# STM32F40x register map
File version: 1.5
Registers are 32-bit, read-write, reset 0x0 unless marked. A register's access mark holds for its fields unless they carry their own. Offsets are from the block's base; [hi:lo] are bit positions; {n}, {i} and the like mark numbered series; 'fields as' and 'values as' point back to an identical list.

## RTC（实时时钟） — 实时时钟：日历/闹钟/唤醒 | Real-time clock
Base 0x40002800
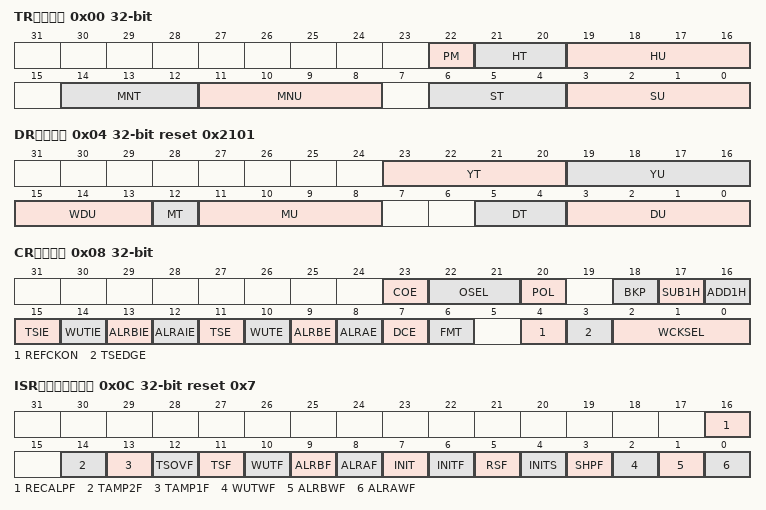
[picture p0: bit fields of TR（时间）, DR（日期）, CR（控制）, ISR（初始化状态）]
0x00 TR（时间） — BCD 时间（时/分/秒） | time register
  [22] PM — AM/PM notation
  [21:20] HT — Hour tens in BCD format
  [19:16] HU — Hour units in BCD format
  [14:12] MNT — Minute tens in BCD format
  [11:8] MNU — Minute units in BCD format
  [6:4] ST — Second tens in BCD format
  [3:0] SU — Second units in BCD format
0x04 DR（日期） reset 0x2101 — BCD 日期（年/月/日/星期） | date register
  [23:20] YT — Year tens in BCD format
  [19:16] YU — Year units in BCD format
  [15:13] WDU — Week day units
  [12] MT — Month tens in BCD format
  [11:8] MU — Month units in BCD format
  [5:4] DT — Date tens in BCD format
  [3:0] DU — Date units in BCD format
0x08 CR（控制） — 控制：日历/闹钟/中断/校准使能 | control register
  [23] COE — Calibration output enable
  [22:21] OSEL — Output selection
  [20] POL — Output polarity
  [18] BKP — Backup
  [17] SUB1H — Subtract 1 hour (winter time change)
  [16] ADD1H — Add 1 hour (summer time change)
  [15] TSIE — Time-stamp interrupt enable
  [14] WUTIE — Wakeup timer interrupt enable
  [13] ALRBIE — Alarm B interrupt enable
  [12] ALRAIE — Alarm A interrupt enable
  [11] TSE — Time stamp enable
  [10] WUTE — Wakeup timer enable
  [9] ALRBE — Alarm B enable
  [8] ALRAE — Alarm A enable
  [7] DCE — Coarse digital calibration enable
  [6] FMT — Hour format
  [4] REFCKON — Reference clock detection enable (50 or 60 Hz)
  [3] TSEDGE — Time-stamp event active edge
  [2:0] WCKSEL — Wakeup clock selection
0x0C ISR（初始化状态） access per field reset 0x7 — 初始化/同步/闹钟 标志 | initialization and status register
  [16] RECALPF ro — Recalibration pending Flag
  [14] TAMP2F rw — TAMPER2 detection flag
  [13] TAMP1F rw — Tamper detection flag
  [12] TSOVF rw — Time-stamp overflow flag
  [11] TSF rw — Time-stamp flag
  [10] WUTF rw — Wakeup timer flag
  [9] ALRBF rw — Alarm B flag
  [8] ALRAF rw — Alarm A flag
  [7] INIT rw — Initialization mode
  [6] INITF ro — Initialization flag
  [5] RSF rw — Registers synchronization flag
  [4] INITS ro — Initialization status flag
  [3] SHPF rw — Shift operation pending
  [2] WUTWF ro — Wakeup timer write flag
  [1] ALRBWF ro — Alarm B write flag
  [0] ALRAWF ro — Alarm A write flag
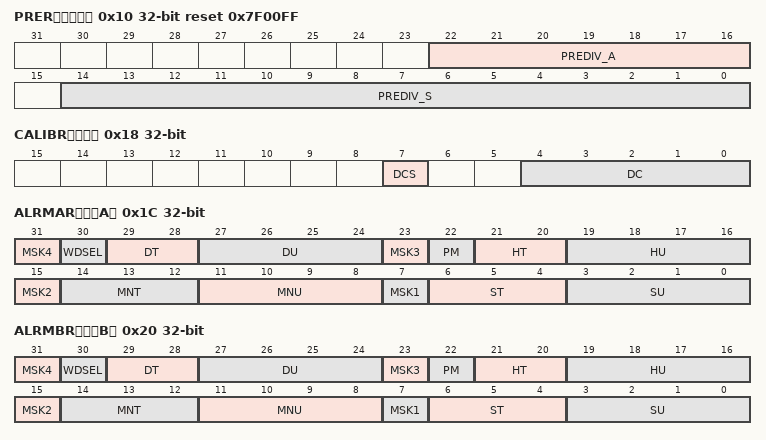
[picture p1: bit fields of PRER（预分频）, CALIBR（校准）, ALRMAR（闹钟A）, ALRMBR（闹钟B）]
0x10 PRER（预分频） reset 0x7F00FF — 异步/同步 预分频 | prescaler register
  [22:16] PREDIV_A — Asynchronous prescaler factor
  [14:0] PREDIV_S — Synchronous prescaler factor
0x14 WUTR（唤醒定时器） reset 0xFFFF — 唤醒定时器重装载 | wakeup timer register
  [15:0] WUT — Wakeup auto-reload value bits
0x18 CALIBR（校准） — 粗校准（建议用 CALR） | calibration register
  [7] DCS — Digital calibration sign
  [4:0] DC — Digital calibration
0x1C ALRMAR（闹钟A） — 闹钟 A 时间掩码 | alarm A register
  [31] MSK4 — Alarm A date mask
  [30] WDSEL — Week day selection
  [29:28] DT — Date tens in BCD format
  [27:24] DU — Date units or day in BCD format
  [23] MSK3 — Alarm A hours mask
  [22] PM — AM/PM notation
  [21:20] HT — Hour tens in BCD format
  [19:16] HU — Hour units in BCD format
  [15] MSK2 — Alarm A minutes mask
  [14:12] MNT — Minute tens in BCD format
  [11:8] MNU — Minute units in BCD format
  [7] MSK1 — Alarm A seconds mask
  [6:4] ST — Second tens in BCD format
  [3:0] SU — Second units in BCD format
0x20 ALRMBR（闹钟B） — 闹钟 B 时间掩码 | alarm B register
  [31] MSK4 — Alarm B date mask
  [30] WDSEL — Week day selection
  [29:28] DT — Date tens in BCD format
  [27:24] DU — Date units or day in BCD format
  [23] MSK3 — Alarm B hours mask
  [22] PM — AM/PM notation
  [21:20] HT — Hour tens in BCD format
  [19:16] HU — Hour units in BCD format
  [15] MSK2 — Alarm B minutes mask
  [14:12] MNT — Minute tens in BCD format
  [11:8] MNU — Minute units in BCD format
  [7] MSK1 — Alarm B seconds mask
  [6:4] ST — Second tens in BCD format
  [3:0] SU — Second units in BCD format
0x24 WPR（写保护） wo — 写保护密钥（解/锁） | write protection register
  [7:0] KEY — Write protection key
0x28 SSR（子秒） ro — 亚秒（亚秒累加）值 | sub second register
  [15:0] SS — Sub second value
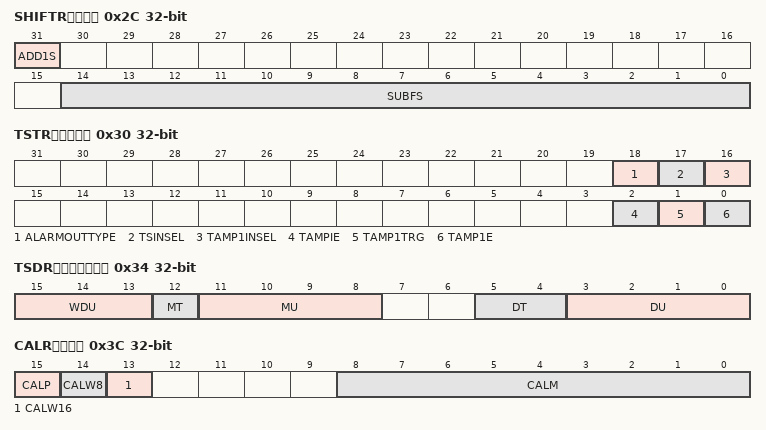
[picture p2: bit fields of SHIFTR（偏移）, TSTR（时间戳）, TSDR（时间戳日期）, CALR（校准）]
0x2C SHIFTR（偏移） wo — 时间偏移（加减）寄存器 | shift control register
  [31] ADD1S — Add one second
  [14:0] SUBFS — Subtract a fraction of a second
0x30 TSTR（时间戳） ro — 时间戳时间 | time stamp time register
  [18] ALARMOUTTYPE — AFO_ALARM output type
  [17] TSINSEL — TIMESTAMP mapping
  [16] TAMP1INSEL — TAMPER1 mapping
  [2] TAMPIE — Tamper interrupt enable
  [1] TAMP1TRG — Active level for tamper 1
  [0] TAMP1E — Tamper 1 detection enable
0x34 TSDR（时间戳日期） ro — 时间戳日期 | time stamp date register
  [15:13] WDU — Week day units
  [12] MT — Month tens in BCD format
  [11:8] MU — Month units in BCD format
  [5:4] DT — Date tens in BCD format
  [3:0] DU — Date units in BCD format
0x38 TSSSR（时间戳亚秒） ro — 时间戳亚秒 | timestamp sub second register
  [15:0] SS — Sub second value
0x3C CALR（校准） — 细校准（温度补偿） | calibration register
  [15] CALP — Increase frequency of RTC by 488.5 ppm
  [14] CALW8 — Use an 8-second calibration cycle period
  [13] CALW16 — Use a 16-second calibration cycle period
  [8:0] CALM — Calibration minus
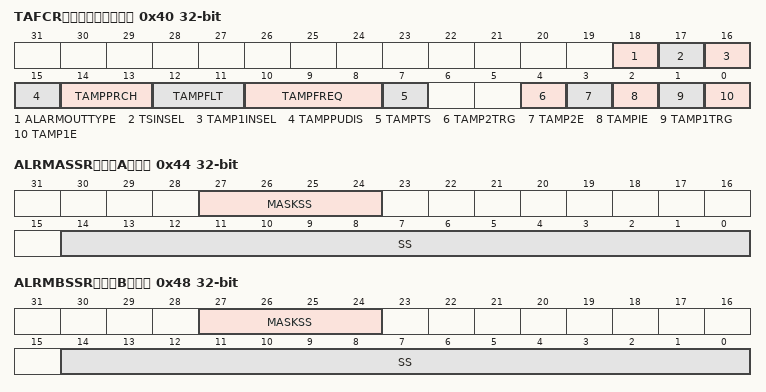
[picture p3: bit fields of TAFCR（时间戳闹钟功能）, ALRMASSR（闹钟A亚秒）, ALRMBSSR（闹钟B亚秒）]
0x40 TAFCR（时间戳闹钟功能） — 时间戳/闹钟 输出与功能 | tamper and alternate function configuration register
  [18] ALARMOUTTYPE — AFO_ALARM output type
  [17] TSINSEL — TIMESTAMP mapping
  [16] TAMP1INSEL — TAMPER1 mapping
  [15] TAMPPUDIS — TAMPER pull-up disable
  [14:13] TAMPPRCH — Tamper precharge duration
  [12:11] TAMPFLT — Tamper filter count
  [10:8] TAMPFREQ — Tamper sampling frequency
  [7] TAMPTS — Activate timestamp on tamper detection event
  [4] TAMP2TRG — Active level for tamper 2
  [3] TAMP2E — Tamper 2 detection enable
  [2] TAMPIE — Tamper interrupt enable
  [1] TAMP1TRG — Active level for tamper 1
  [0] TAMP1E — Tamper 1 detection enable
0x44 ALRMASSR（闹钟A亚秒） — 闹钟 A 亚秒掩码 | alarm A sub second register
  [27:24] MASKSS — Mask the most-significant bits starting at this bit
  [14:0] SS — Sub seconds value
0x48 ALRMBSSR（闹钟B亚秒） — 闹钟 B 亚秒掩码 | alarm B sub second register
  fields as ALRMASSR（闹钟A亚秒）
{0x50+4i} BKP{i}R（备份{i}） (i=0..19) — 备份寄存器 {i}（Vbat 掉电保留） | backup register
  [31:0] BKP
